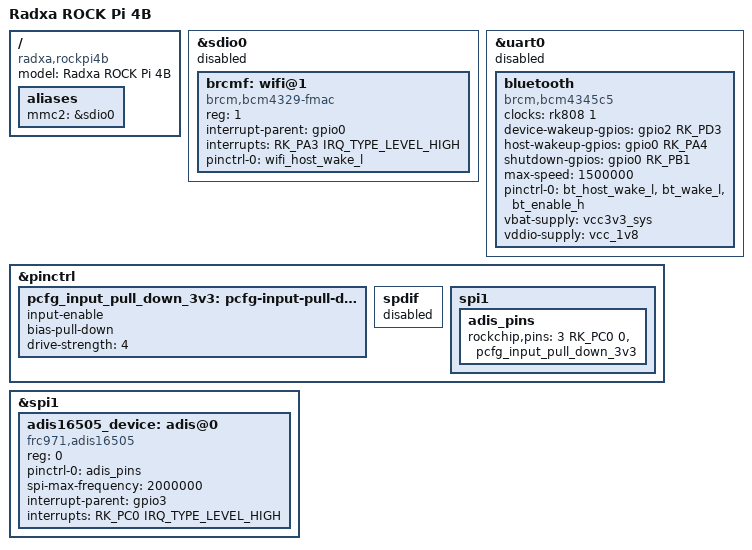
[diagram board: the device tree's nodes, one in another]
// SPDX-License-Identifier: (GPL-2.0+ OR MIT)
/*
 * Copyright (c) 2019 Akash Gajjar <Akash_Gajjar@mentor.com>
 * Copyright (c) 2019 Pragnesh Patel <Pragnesh_Patel@mentor.com>
 */

/dts-v1/;
#include "rk3399-rock-pi-4.dtsi"

/ {
	model = "Radxa ROCK Pi 4B";
	compatible = "radxa,rockpi4b", "radxa,rockpi4", "rockchip,rk3399";

	aliases {
		mmc2 = &sdio0;
	};
};

&sdio0 {
	status = "disabled";

	brcmf: wifi@1 {
		compatible = "brcm,bcm4329-fmac";
		reg = <1>;
		interrupt-parent = <&gpio0>;
		interrupts = <RK_PA3 IRQ_TYPE_LEVEL_HIGH>;
		interrupt-names = "host-wake";
		pinctrl-names = "default";
		pinctrl-0 = <&wifi_host_wake_l>;
	};
};

&uart0 {
	status = "disabled";

	bluetooth {
		compatible = "brcm,bcm4345c5";
		clocks = <&rk808 1>;
		clock-names = "lpo";
		device-wakeup-gpios = <&gpio2 RK_PD3 GPIO_ACTIVE_HIGH>;
		host-wakeup-gpios = <&gpio0 RK_PA4 GPIO_ACTIVE_HIGH>;
		shutdown-gpios = <&gpio0 RK_PB1 GPIO_ACTIVE_HIGH>;
		max-speed = <1500000>;
		pinctrl-names = "default";
		pinctrl-0 = <&bt_host_wake_l &bt_wake_l &bt_enable_h>;
		vbat-supply = <&vcc3v3_sys>;
		vddio-supply = <&vcc_1v8>;
	};
};

&pinctrl {
	pcfg_input_pull_down_3v3: pcfg-input-pull-down-3v3 {
		input-enable;
		bias-pull-down;
		drive-strength = <4>;
	};

	spdif {
		status = "disabled";
	};

	spi1 {
		adis_pins: adis_pins {
			rockchip,pins = <3 RK_PC0 0 &pcfg_input_pull_down_3v3>;
			//brcm,function = <0>; // input
		};
	};
};

&spi1 {
	status = "okay";

	adis16505_device: adis@0 {
		compatible = "frc971,adis16505";
		reg = <0>;
		pinctrl-names = "default";
		pinctrl-0 = <&adis_pins>;

		spi-max-frequency = <2000000>;
		//data-ready = <&gpio 12 0>;

		interrupt-parent = <&gpio3>;
		// 2 -> edge....
		interrupts = <RK_PC0 IRQ_TYPE_LEVEL_HIGH>; /* low level triggered */
	};
};
